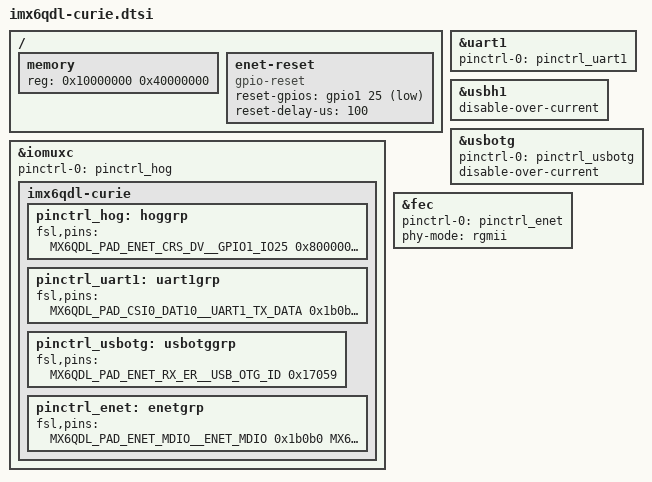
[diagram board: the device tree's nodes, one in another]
/*
 * Copyright 2015 Shanghai Zhixing Information Technology Co.,Ltd.
 */

/ {
	memory {
		reg = <0x10000000 0x40000000>;
	};

	enet-reset {
		compatible = "gpio-reset";
		reset-gpios = <&gpio1 25 GPIO_ACTIVE_LOW>;
		reset-delay-us = <100>;
		#reset-cells = <0>;
	};
};

&iomuxc {
	pinctrl-names = "default";
	pinctrl-0 = <&pinctrl_hog>;

	imx6qdl-curie {
		pinctrl_hog: hoggrp {
			fsl,pins = <
				MX6QDL_PAD_ENET_CRS_DV__GPIO1_IO25 0x80000000
			>;
		};

		pinctrl_uart1: uart1grp {
			fsl,pins = <
				MX6QDL_PAD_CSI0_DAT10__UART1_TX_DATA	0x1b0b1
				MX6QDL_PAD_CSI0_DAT11__UART1_RX_DATA	0x1b0b1
			>;
		};

		pinctrl_usbotg: usbotggrp {
			fsl,pins = <
				MX6QDL_PAD_ENET_RX_ER__USB_OTG_ID	0x17059
			>;
		};

		pinctrl_enet: enetgrp {
			fsl,pins = <
				MX6QDL_PAD_ENET_MDIO__ENET_MDIO		0x1b0b0
				MX6QDL_PAD_ENET_MDC__ENET_MDC		0x1b0b0
				MX6QDL_PAD_RGMII_TXC__RGMII_TXC		0x1b0b0
				MX6QDL_PAD_RGMII_TD0__RGMII_TD0		0x1b0b0
				MX6QDL_PAD_RGMII_TD1__RGMII_TD1		0x1b0b0
				MX6QDL_PAD_RGMII_TD2__RGMII_TD2		0x1b0b0
				MX6QDL_PAD_RGMII_TD3__RGMII_TD3		0x1b0b0
				MX6QDL_PAD_RGMII_TX_CTL__RGMII_TX_CTL	0x1b0b0
				MX6QDL_PAD_ENET_REF_CLK__ENET_TX_CLK	0x1b0b0
				MX6QDL_PAD_RGMII_RXC__RGMII_RXC		0x1b0b0
				MX6QDL_PAD_RGMII_RD0__RGMII_RD0		0x1b0b0
				MX6QDL_PAD_RGMII_RD1__RGMII_RD1		0x1b0b0
				MX6QDL_PAD_RGMII_RD2__RGMII_RD2		0x1b0b0
				MX6QDL_PAD_RGMII_RD3__RGMII_RD3		0x1b0b0
				MX6QDL_PAD_RGMII_RX_CTL__RGMII_RX_CTL	0x1b0b0
				MX6QDL_PAD_GPIO_16__ENET_REF_CLK	0x4001b0a8
			>;
		};

	};
};

&uart1 {
	pinctrl-names = "default";
	pinctrl-0 = <&pinctrl_uart1>;
	status = "okay";
};

&usbh1 {
	disable-over-current;
	status = "okay";
};

&usbotg {
	pinctrl-names = "default";
	pinctrl-0 = <&pinctrl_usbotg>;
	disable-over-current;
	status = "okay";
};

&fec {
	pinctrl-names = "default";
	pinctrl-0 = <&pinctrl_enet>;
	phy-mode = "rgmii";
	status = "okay";
};
